# M365 register map
File version: 0.1
Registers are 32-bit, read-write, reset 0x0 unless marked. A register's access mark holds for its fields unless they carry their own. Offsets are from the block's base; [hi:lo] are bit positions; {n}, {i} and the like mark numbered series.

## PG — General Purpose Input_Output Port (PG)
Base 0x400C0600
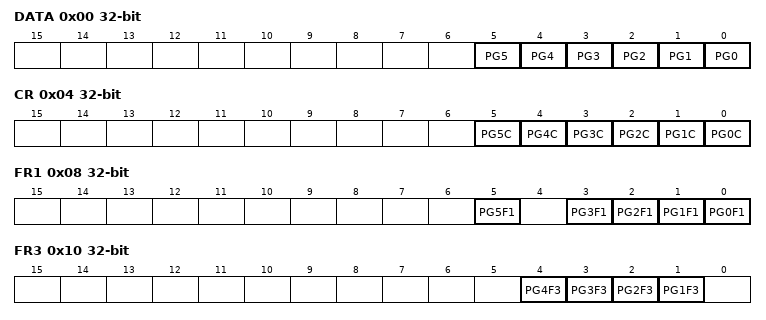
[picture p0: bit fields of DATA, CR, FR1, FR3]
0x00 DATA — PG Data Register
  [n] PG{n} (n=0..5)
0x04 CR — PG Control Register
  [n] PG{n}C (n=0..5)
0x08 FR1 — PG Function Register 2
  [5] PG5F1, [n] PG{n}F1 (n=0..3)
0x10 FR3 — PG Function Register 3
  [n] PG{n}F3 (n=1..4)
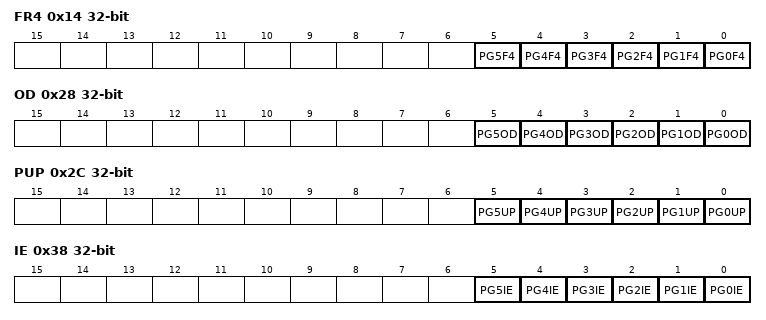
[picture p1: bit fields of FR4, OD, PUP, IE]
0x14 FR4 — PG Function Register 4
  [n] PG{n}F4 (n=0..5)
0x28 OD — PG Open Drain Control Register
  [n] PG{n}OD (n=0..5)
0x2C PUP — PG Pull-Up Control Register
  [n] PG{n}UP (n=0..5)
0x38 IE — PG Input Enable Control Register
  [n] PG{n}IE (n=0..5)

## PH — General Purpose Input_Output Port (PH)
Base 0x400C0700
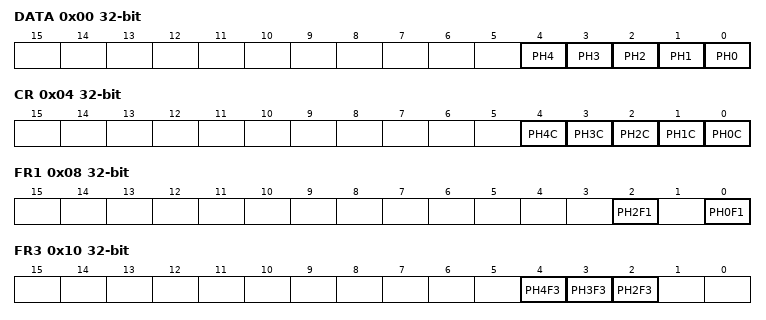
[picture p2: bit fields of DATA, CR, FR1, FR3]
0x00 DATA — PH Data Register
  [n] PH{n} (n=0..4)
0x04 CR — PH Control Register
  [n] PH{n}C (n=0..4)
0x08 FR1 — PH Function Register 1
  [2] PH2F1, [0] PH0F1
0x10 FR3 — PH Function Register 3
  [4] PH4F3, [3] PH3F3, [2] PH2F3
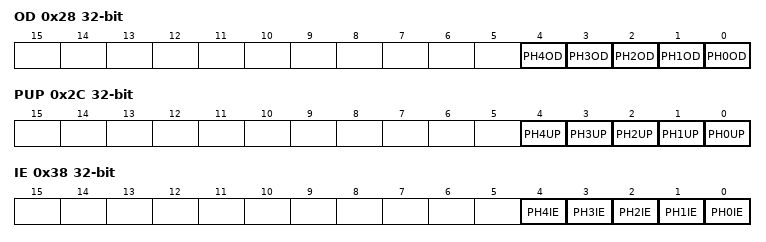
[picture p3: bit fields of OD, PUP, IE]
0x28 OD — PH Open Drain Control Register
  [n] PH{n}OD (n=0..4)
0x2C PUP — PH Pull-Up Control Register
  [n] PH{n}UP (n=0..4)
0x38 IE — PH Input Enable Control Register
  [n] PH{n}IE (n=0..4)

## PI — General Purpose Input_Output Port (PI)
Base 0x400C0800
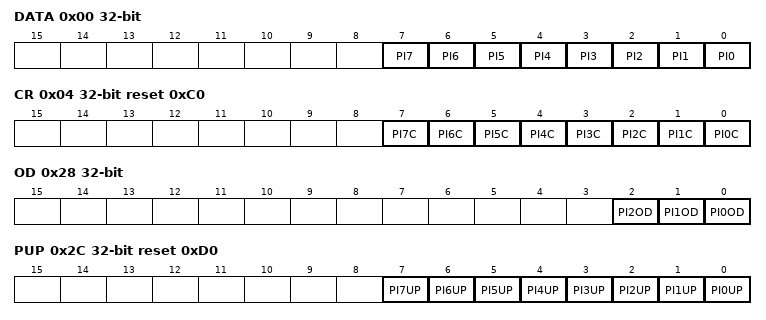
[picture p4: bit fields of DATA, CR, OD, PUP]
0x00 DATA — PI Data Register
  [n] PI{n} (n=0..7)
0x04 CR reset 0xC0 — PI Control Register
  [n] PI{n}C (n=0..7)
0x28 OD — PI Open Drain Control Register
  [2] PI2OD, [1] PI1OD, [0] PI0OD
0x2C PUP reset 0xD0 — PI Pull-Up Control Register
  [n] PI{n}UP (n=0..7)
0x30 PDN reset 0x8 — PI Pull-Down Control Register
  [3] PI3DN
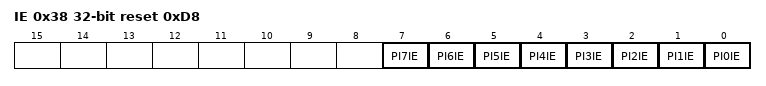
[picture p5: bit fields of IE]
0x38 IE reset 0xD8 — PI Input Enable Control Register
  [n] PI{n}IE (n=0..7)

## PJ — General Purpose Input_Output Port (PJ)
Base 0x400C0900
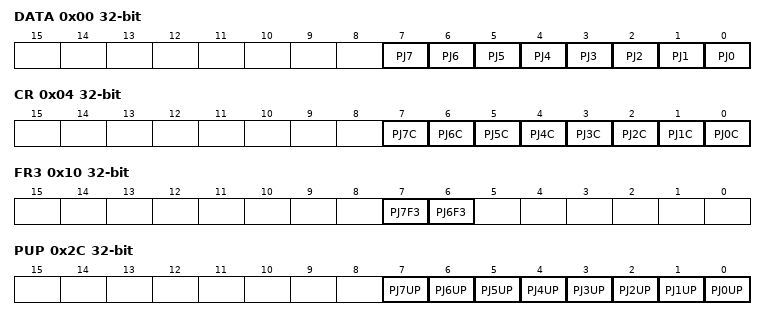
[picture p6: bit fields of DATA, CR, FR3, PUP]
0x00 DATA — PJ Data Register
  [n] PJ{n} (n=0..7)
0x04 CR — PJ Control Register
  [n] PJ{n}C (n=0..7)
0x0C FR2 — PJ Function Register 2
  [7] PJ7F2
0x10 FR3 — PJ Function Register 3
  [7] PJ7F3, [6] PJ6F3
0x2C PUP — PJ Pull-Up Control Register
  [n] PJ{n}UP (n=0..7)
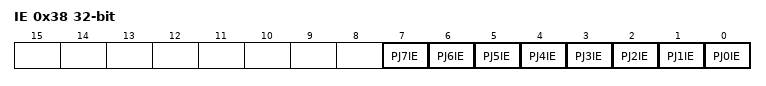
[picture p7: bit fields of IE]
0x38 IE — PJ Input Enable Control Register
  [n] PJ{n}IE (n=0..7)

## PK — General Purpose Input_Output Port (PK)
Base 0x400C0A00
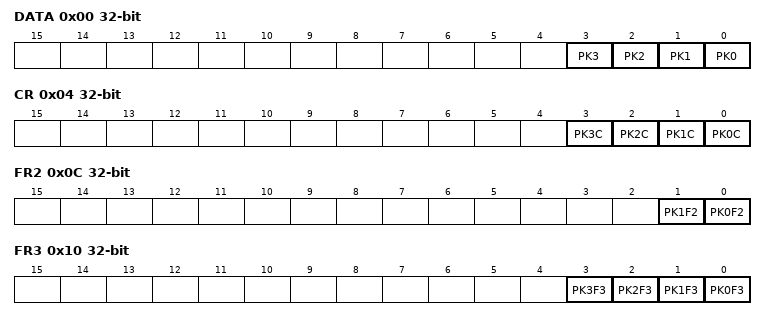
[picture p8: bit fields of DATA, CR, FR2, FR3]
0x00 DATA — PK Data Register
  [n] PK{n} (n=0..3)
0x04 CR — PK Control Register
  [n] PK{n}C (n=0..3)
0x0C FR2 — PK Function Register 2
  [1] PK1F2, [0] PK0F2
0x10 FR3 — PK Function Register 3
  [n] PK{n}F3 (n=0..3)
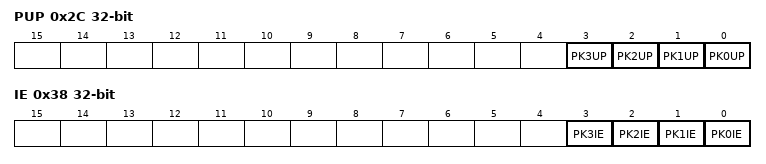
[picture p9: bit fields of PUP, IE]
0x2C PUP — PK Pull-Up Control Register
  [n] PK{n}UP (n=0..3)
0x38 IE — PK Input Enable Control Register
  [n] PK{n}IE (n=0..3)

## TB0 — 16-bit Timer_Event Counter (TB)
Base 0x400C4000
Same registers: TB{n} {0x400C4000+0x100*n} (n=1..9)
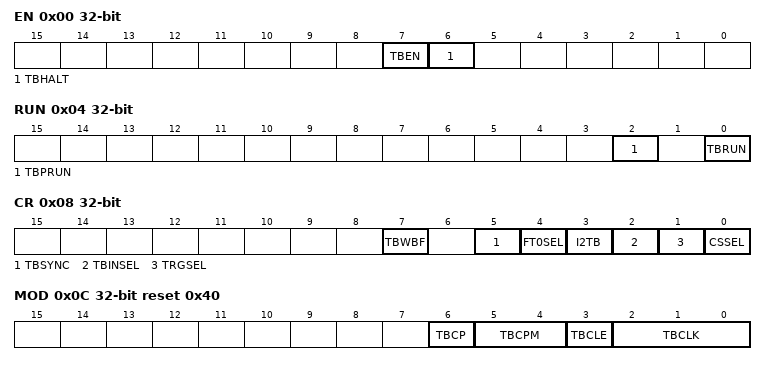
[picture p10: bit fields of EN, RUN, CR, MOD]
0x00 EN — TB Enable Register
  [7] TBEN, [6] TBHALT
0x04 RUN — TB RUN Register
  [2] TBPRUN, [0] TBRUN
0x08 CR — TB Control Register
  [7] TBWBF, [5] TBSYNC, [4] FT0SEL, [3] I2TB, [2] TBINSEL, [1] TRGSEL, [0] CSSEL
0x0C MOD reset 0x40 — TB Mode Register
  [6] TBCP wo, [5:4] TBCPM, [3] TBCLE, [2:0] TBCLK
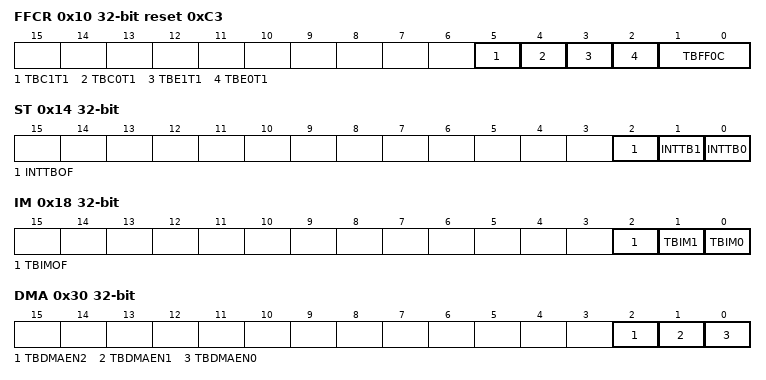
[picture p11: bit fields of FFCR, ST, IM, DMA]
0x10 FFCR reset 0xC3 — TB Flip-Flop Control Register
  [5] TBC1T1, [4] TBC0T1, [3] TBE1T1, [2] TBE0T1, [1:0] TBFF0C
0x14 ST ro — TB Status Register
  [2] INTTBOF, [1] INTTB1, [0] INTTB0
0x18 IM — TB Interrupt Mask Register
  [2] TBIMOF, [1] TBIM1, [0] TBIM0
0x1C UC ro — TB Read Capture Register
  [15:0] UC
0x20 RG0 — TB RG0 Timer Register
  [15:0] TBRG0
0x24 RG1 — TB RG1 Timer Register
  [15:0] TBRG1
0x28 CP0 ro (reset mask 0xFFFF0000) — TB CP0 Capture Register
  [15:0] TBCP0
0x2C CP1 ro (reset mask 0xFFFF0000) — TB CP1 Capture Register
  [15:0] TBCP1
0x30 DMA — TB DMA Enable Register
  [2] TBDMAEN2, [1] TBDMAEN1, [0] TBDMAEN0

## SBI0 — Serial Bus Interface (SBI)
Base 0x400E0000
Same registers: SBI1 0x400E0100
0x00 CR0 — SBI Control Register 0
  [7] SBIEN
0x04 CR1_A reset 0x3 — SBI Control Register 1 (I2C Mode)
  [7:5] BC, [4] ACK, [0] SWRMON ro, [2:0] SCK wo
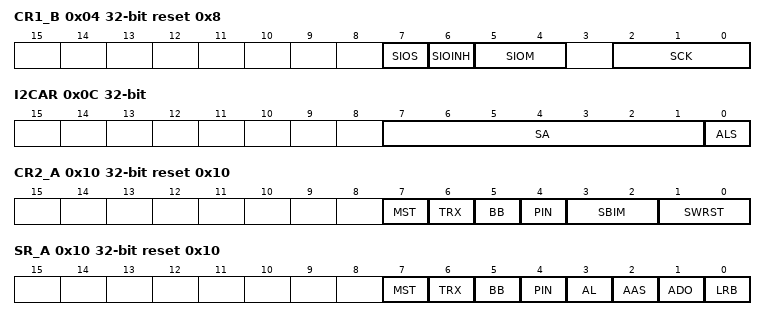
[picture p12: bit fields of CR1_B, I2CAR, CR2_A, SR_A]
0x04 CR1_B reset 0x8 (SBI_CR1 view) — SBI Control Register 1 (SIO Mode)
  [7] SIOS, [6] SIOINH, [5:4] SIOM, [2:0] SCK
0x08 DBR — SBI Data Buffer Register
  [7:0] DB
0x0C I2CAR — SBI I2C Bus Address Register
  [7:1] SA, [0] ALS
0x10 CR2_A wo reset 0x10 — SBI Control Register 2 (I2C Mode)
  [7] MST, [6] TRX, [5] BB, [4] PIN, [3:2] SBIM, [1:0] SWRST
0x10 CR2_B wo reset 0xF3 (SBI_CR2 view) — SBI Control Register 2 (SIO Mode)
  [3:2] SBIM
0x10 SR_A ro reset 0x10 — SBI Status Register (I2C Mode)
  [7] MST, [6] TRX, [5] BB, [4] PIN, [3] AL, [2] AAS, [1] ADO, [0] LRB
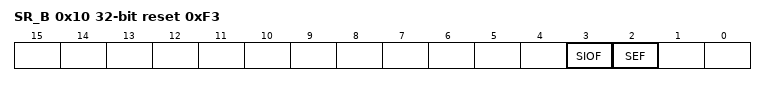
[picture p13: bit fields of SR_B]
0x10 SR_B ro reset 0xF3 (SBI_SR view) — SBI Status Register (SIO Mode)
  [3] SIOF, [2] SEF
0x14 BR0 reset 0xBE — SBI Baud Rate Register 0
  [6] I2SBI

## SC0 — Serial Channel (SC)
Base 0x400E1000
Same registers: SC1 0x400E1100
0x00 EN — SC Enable Register
  [0] SIOE
0x04 BUF — SC Buffer Register
  [7:0] TB_RB
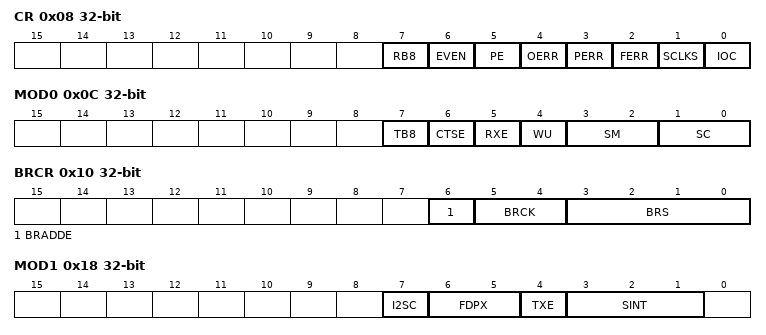
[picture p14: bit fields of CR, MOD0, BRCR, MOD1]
0x08 CR — SC Control Register
  [7] RB8 ro, [6] EVEN, [5] PE, [4] OERR ro, [3] PERR ro, [2] FERR ro, [1] SCLKS, [0] IOC
0x0C MOD0 — SC Mode Control Register 0
  [7] TB8, [6] CTSE, [5] RXE, [4] WU, [3:2] SM, [1:0] SC
0x10 BRCR — SC Baud Rate Generator Control Register
  [6] BRADDE, [5:4] BRCK, [3:0] BRS
0x14 BRADD — SC Baud Rate Generator Control Register 2
  [3:0] BRK
0x18 MOD1 — SC Mode Control Register 1
  [7] I2SC, [6:5] FDPX, [4] TXE, [3:1] SINT
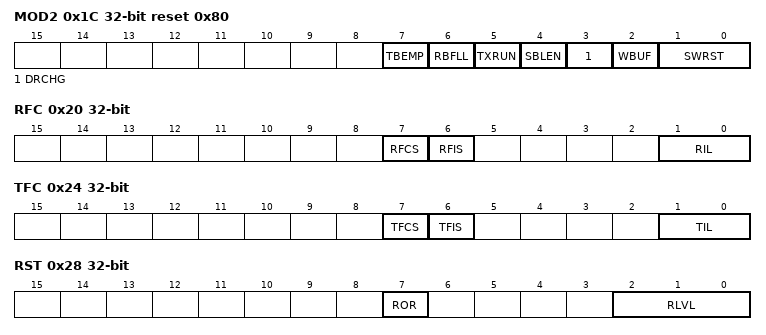
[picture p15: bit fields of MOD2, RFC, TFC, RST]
0x1C MOD2 reset 0x80 — SC Mode Control Register 2
  [7] TBEMP ro, [6] RBFLL ro, [5] TXRUN ro, [4] SBLEN, [3] DRCHG, [2] WBUF, [1:0] SWRST wo
0x20 RFC — SC RX FIFO Configuration Register
  [7] RFCS wo, [6] RFIS, [1:0] RIL
0x24 TFC — SC TX FIFO Configuration Register
  [7] TFCS wo, [6] TFIS, [1:0] TIL
0x28 RST ro — SC RX FIFO Status Register
  [7] ROR, [2:0] RLVL
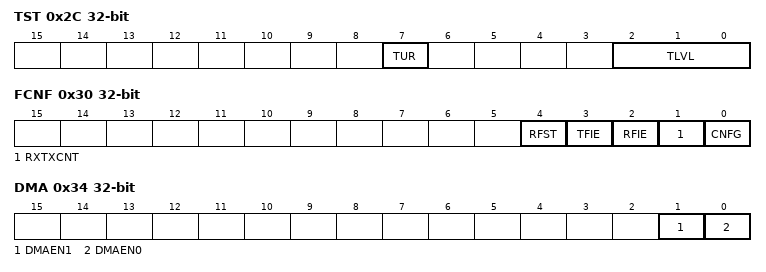
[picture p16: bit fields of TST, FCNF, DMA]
0x2C TST ro — SC TX FIFO Status Register
  [7] TUR, [2:0] TLVL
0x30 FCNF — SC FIFO Configuration Register
  [4] RFST, [3] TFIE, [2] RFIE, [1] RXTXCNT, [0] CNFG
0x34 DMA — SC DMA Enable Register
  [1] DMAEN1, [0] DMAEN0

## WD — Watchdog Timer (WD)
Base 0x400F2000
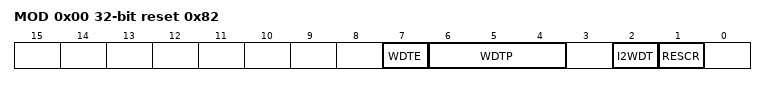
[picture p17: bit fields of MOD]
0x00 MOD reset 0x82 — WD Mode Register
  [7] WDTE, [6:4] WDTP, [2] I2WDT, [1] RESCR
0x04 CR wo (reset mask 0xFFFFFF00) — WD Control Register
  [7:0] WDCR — Disable/Clear Code

## CG — Clock Generator (CG)
Base 0x400F3000
0x00 SYSCR reset 0x10000 — System Control Register
  [20] FCSTOP, [17:16] SCOSEL, [12] FPSEL, [10:8] PRCK, [2:0] GEAR
0x04 OSCCR reset 0x10030 — Oscillation Control Register
  [31:20] WUODR, [19] HWUPSEL, [18] EHOSCSEL, [17] OSCSEL, [16] XEN2, [8] XEN1, [2] PLLON, [1] WUEF ro, [0] WUEON wo
0x08 STBYCR reset 0x103 — Standby Control Register
  [16] DRVE, [2:0] STBY
0x0C PLLSEL — PLL Selection Register
  [15:1] PLLSET, [0] PLLSEL
0x38 USBCTL — USB Clock and Reset Control register
  [9] USBCLKSEL, [8] USBCLKEN
0x3C PROTECT reset 0xC1
  [7:0] CGPROTECT
0x40 IMCGA reset 0x20202020 — CG Interrupt Mode Control Register A
  [8n+6:8n+4] EMCG{n} (n=0..3), [8n+3:8n+2] EMST{n} ro (n=0..3), [8n] INT{n}EN (n=0..3)
0x44 IMCGB reset 0x20202020 — CG Interrupt Mode Control Register B
  [8n-26:8n-28] EMCG{n} (n=4..7), [8n-29:8n-30] EMST{n} ro (n=4..7), [8n-32] INT{n}EN (n=4..7)
0x48 IMCGC reset 0x20202020 — CG Interrupt Mode Control Register C
  [30:28] EMCGB, [27:26] EMSTB ro, [24] INTBEN, [22:20] EMCGA, [19:18] EMSTA ro, [16] INTAEN, [14:12] EMCG9, [11:10] EMST9 ro, [8] INT9EN, [6:4] EMCG8, [3:2] EMST8 ro, [0] INT8EN
0x60 ICRCG wo — CG Interrupt Request Clear Register
  [4:0] ICRCG
0x64 RSTFLG reset 0x1 — Reset Flag Register
  [4] DBGRSTF, [3] STOP2RSTF, [2] WDTRSTF, [0] PINRSTF
0x68 NMIFLG ro — NMI Flag Register
  [1] NMIFLG1, [0] NMIFLG0

## FC — Flash Control (FC)
Base 0x41FFF010
0x00 SECBIT reset 0x1 — FC Security Bit Register
  [0] SECBIT
0x10 FLCS ro reset 0xFFFFFFFFFFFF0001 — FC Flash Control Register
  [21:16] BLPRO, [0] RDY_BSY
